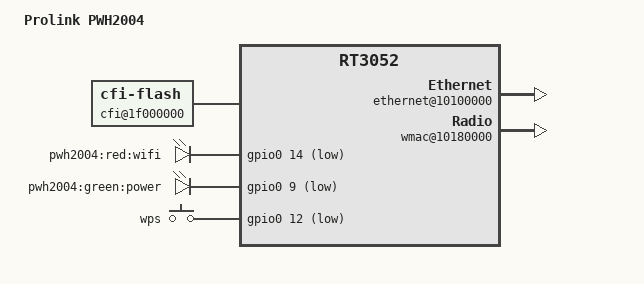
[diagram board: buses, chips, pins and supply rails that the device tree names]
/dts-v1/;

/include/ "rt3050.dtsi"

/ {
	#address-cells = <1>;
	#size-cells = <1>;
	compatible = "PWH2004", "ralink,rt3052-soc";
	model = "Prolink PWH2004";

	memorydetect {
		ralink,memory = <0x0 0x200000 0x4000000>;
	};

	chosen {
		bootargs = "console=ttyS0,57600 mtdparts=1f000000.cfi:192k(u-boot)ro,64k(u-boot-env)ro,64k(factory)ro,7872k@0x50000(firmware)";
	};

	palmbus@10000000 {
		sysc@0 {
			ralink,pinmmux = "i2c", "spi", "uartlite", "jtag", "mdio", "sdram", "rgmii";
			ralink,uartmux = "gpio";
			ralink,wdtmux = <1>;
		};

		gpio0: gpio@600 {
			status = "okay";
		};

	};

	cfi@1f000000 {
		compatible = "cfi-flash";
		reg = <0x1f000000 0x800000>;

		bank-width = <2>;
		device-width = <2>;
		#address-cells = <1>;
		#size-cells = <1>;
	};

	gpio-leds {
		compatible = "gpio-leds";
		wifi {
			label = "pwh2004:red:wifi";
			gpios = <&gpio0 14 1>;
		};
		power {
			label = "pwh2004:green:power";
			gpios = <&gpio0 9 1>;
		};
	};

	gpio-keys-polled {
		compatible = "gpio-keys-polled";
		#address-cells = <1>;
		#size-cells = <0>;
		poll-interval = <20>;
		wps {
			label = "wps";
			gpios = <&gpio0 12 1>;
			linux,code = <0x198>;
		};
	};

	ethernet@10100000 {
		status = "okay";
	};

	esw@10110000 {
		status = "okay";
		ralink,portmap = <0x2f>;
	};

	wmac@10180000 {
		status = "okay";
	};
};
